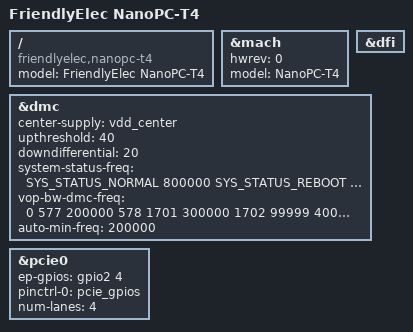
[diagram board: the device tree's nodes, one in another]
/*
 * Copyright (c) 2018 FriendlyElec Computer Tech. Co., Ltd.
 * (http://www.friendlyarm.com)
 *
 * This program is free software; you can redistribute it and/or
 * modify it under the terms of the GNU General Public License
 * as published by the Free Software Foundation; either version 2
 * of the License, or (at your option) any later version.
 *
 * This program is distributed in the hope that it will be useful,
 * but WITHOUT ANY WARRANTY; without even the implied warranty of
 * MERCHANTABILITY or FITNESS FOR A PARTICULAR PURPOSE.  See the
 * GNU General Public License for more details.
 *
 * You should have received a copy of the GNU General Public License
 * along with this program.  If not, see <http://www.gnu.org/licenses/>.
 */

/dts-v1/;
#include "rk3399-nanopi4-common.dtsi"

/ {
	model = "FriendlyElec NanoPC-T4";
	compatible = "friendlyelec,nanopc-t4", "rockchip,rk3399";
};

&mach {
	hwrev = <0>;
	model = "NanoPC-T4";
};

&dfi {
	status = "okay";
};

&dmc {
	status = "okay";
	center-supply = <&vdd_center>;
	upthreshold = <40>;
	downdifferential = <20>;
	system-status-freq = <
		/*system status         freq(KHz)*/
		SYS_STATUS_NORMAL       800000
		SYS_STATUS_REBOOT       528000
		SYS_STATUS_SUSPEND      200000
		SYS_STATUS_VIDEO_1080P  200000
		SYS_STATUS_VIDEO_4K     600000
		SYS_STATUS_VIDEO_4K_10B 800000
		SYS_STATUS_PERFORMANCE  800000
		SYS_STATUS_BOOST        600000
		SYS_STATUS_DUALVIEW     600000
		SYS_STATUS_ISP          600000
	>;
	vop-bw-dmc-freq = <
	/* min_bw(MB/s) max_bw(MB/s) freq(KHz) */
		0       577      200000
		578     1701     300000
		1702    99999    400000
	>;
	auto-min-freq = <200000>;
};

&pcie0 {
	ep-gpios = <&gpio2 4 GPIO_ACTIVE_HIGH>;
	pinctrl-names = "default";
	pinctrl-0 = <&pcie_gpios>;
	num-lanes = <4>;
};
